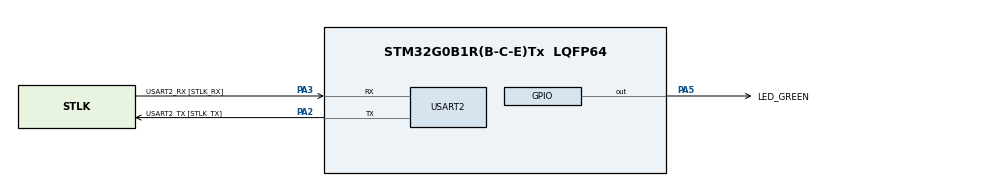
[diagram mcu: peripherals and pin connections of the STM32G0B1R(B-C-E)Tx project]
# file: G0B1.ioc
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FREERTOS.Tasks01=defaultTask,0,256,StartDefaultTask,Default,NULL,Dynamic,NULL,NULL;myTask02_Diagno,-3,256,StartTask02,Default,NULL,Dynamic,NULL,NULL
Mcu.Family=STM32G0
Mcu.Name=STM32G0B1R(B-C-E)Tx
Mcu.Package=LQFP64
NVIC.TIM17_FDCAN_IT1_IRQn=true\:3\:0\:false\:false\:true\:false\:true\:true\:true
NVIC.TimeBase=TIM17_FDCAN_IT1_IRQn
NVIC.TimeBaseIP=TIM17
NVIC.USART2_LPUART2_IRQn=true\:3\:0\:false\:false\:true\:true\:true\:true\:true
PA13.GPIO_Label=TMS
PA13.Mode=Serial_Wire
PA13.Signal=SYS_SWDIO
PA14-BOOT0.GPIO_Label=TCK
PA14-BOOT0.Mode=Serial_Wire
PA14-BOOT0.Signal=SYS_SWCLK
PA2.GPIO_Label=USART2_TX [STLK_TX]
PA2.Mode=Asynchronous
PA2.Signal=USART2_TX
PA3.GPIO_Label=USART2_RX [STLK_RX]
PA3.Mode=Asynchronous
PA3.Signal=USART2_RX
PA5.GPIO_Label=LED_GREEN
PA5.GPIO_Speed=GPIO_SPEED_FREQ_HIGH
PA5.Signal=GPIO_Output
PC13.Mode=SYS_WakeUp1
PC13.Signal=SYS_WKUP2
PC14-OSC32_IN\ (PC14).Mode=LSE-External-Oscillator
PC14-OSC32_IN\ (PC14).Signal=RCC_OSC32_IN
PC15-OSC32_OUT\ (PC15).Mode=LSE-External-Oscillator
PC15-OSC32_OUT\ (PC15).Signal=RCC_OSC32_OUT
PF0-OSC_IN\ (PF0).GPIO_Label=MCO
PF0-OSC_IN\ (PF0).Mode=HSE-External-Clock-Source
PF0-OSC_IN\ (PF0).Signal=RCC_OSC_IN
ProjectManager.HeapSize=0x200
ProjectManager.StackSize=0x400
ProjectManager.TargetToolchain=Makefile
RCC.AHBFreq_Value=16000000
RCC.CortexFreq_Value=16000000
RCC.EXTERNAL_CLOCK_VALUE=12288000
RCC.HCLKFreq_Value=16000000
RCC.HSE_VALUE=8000000
RCC.HSI48_VALUE=48000000
RCC.HSI_VALUE=16000000
RCC.SYSCLKFreq_VALUE=16000000
RCC.USBFreq_Value=48000000
RCC.VCOOutputFreq_Value=128000000
USART2.VirtualMode-Asynchronous=VM_ASYNC
VP_FREERTOS_VS_CMSIS_V1.Mode=CMSIS_V1
VP_SYS_VS_tim17.Mode=TIM17
board=NUCLEO-G0B1RE

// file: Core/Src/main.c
/* USER CODE BEGIN Header */
/**
 ******************************************************************************
 * @file           : main.c
 * @brief          : Main program body
 ******************************************************************************
 * @attention
 *
 * Copyright (c) 2023 STMicroelectronics.
 * All rights reserved.
 *
 * This software is licensed under terms that can be found in the LICENSE file
 * in the root directory of this software component.
 * If no LICENSE file comes with this software, it is provided AS-IS.
 *
 ******************************************************************************
 */
/* USER CODE END Header */
#include "main.h"
#include "cmsis_os.h"

/* USER CODE BEGIN Includes */
#define NANOPRINTF_USE_FIELD_WIDTH_FORMAT_SPECIFIERS 1
#define NANOPRINTF_USE_PRECISION_FORMAT_SPECIFIERS 1
#define NANOPRINTF_USE_FLOAT_FORMAT_SPECIFIERS 1
#define NANOPRINTF_USE_LARGE_FORMAT_SPECIFIERS 1
#define NANOPRINTF_USE_SMALL_FORMAT_SPECIFIERS 1
#define NANOPRINTF_USE_BINARY_FORMAT_SPECIFIERS 0
#define NANOPRINTF_USE_WRITEBACK_FORMAT_SPECIFIERS 0
#define NANOPRINTF_USE_ALT_FORM_FLAG 1
#define NANOPRINTF_IMPLEMENTATION
#include "nanoprintf.h"
#include "trice.h"
#include "trice_sidecar_main_c_B93C5977DE12EC66.h" // trice-bind: keep as last include before this file's Trice calls
/* USER CODE END Includes */

osThreadId defaultTaskHandle;
osThreadId myTask02_DiagnoHandle;
/* USER CODE BEGIN PV */
int LoopCount = 0;
static int TriceLocalLogLineStart = 1; // Keeps record prefixes aligned with logical output lines.
/* USER CODE END PV */

void SystemClock_Config(void);
static void MX_GPIO_Init(void);
static void MX_USART2_UART_Init(void);
void StartDefaultTask(void const* argument);
void StartTask02(void const* argument);

/* USER CODE BEGIN PFP */
static int TriceLocalStampPrefix(char*, size_t, uint16_t, uint8_t, uint32_t);
/* USER CODE END PFP */

/* USER CODE BEGIN 0 */
__weak int _close(void) { return -1; }
__weak int _lseek(void) { return -1; }
__weak int _read(void) { return -1; }
__weak int _write(void) { return -1; }

// TriceLocalUartWrite is intentionally blocking: only the low-priority logging
// task calls it, while producer tasks and interrupts merely enqueue Trices.
static void TriceLocalUartWrite(const char* text, size_t length) {
	for (size_t index = 0; index < length; ++index) {
		while (!LL_USART_IsActiveFlag_TXE_TXFNF(USART2)) {
		}
		LL_USART_TransmitData8(USART2, (uint8_t)text[index]);
	}
	if (length != 0u) {
		TriceLocalLogLineStart = text[length - 1u] == '\n' || text[length - 1u] == '\r';
	}
}

/* USER CODE END 0 */

int main(void) {
	/* USER CODE BEGIN 1 */
#if !TRICE_OFF
	TriceInit();
#endif
	/* USER CODE END 1 */

	/* MCU Configuration--------------------------------------------------------*/

	/* Reset of all peripherals, Initializes the Flash interface and the Systick. */
	HAL_Init();

	/* Configure the system clock */
	SystemClock_Config();

	/* Initialize all configured peripherals */
	MX_GPIO_Init();
	MX_USART2_UART_Init();
	/* USER CODE BEGIN 2 */
	// nanoprintf has the snprintf semantics required by both local-log hooks.
	// Trice-specific conversions use the selected internal formatter paths.
	UserTriceLogPrintfFn = npf_snprintf;
	UserTriceLogPrefixFn = TriceLocalStampPrefix;
	const uint16_t localLogSamples[] = {1u, 0x2au, 0x1234u};
	trice("msg:G0B1 local logging ready\n");
	triceS("text:runtime=[%s]\n", "hello from G0B1");
	triceS("text:width and precision=[%-12.5s]\n", "abcdefgh");
	trice32("float:single=%+.3f scientific=%.2e\n", aFloat(3.125f), aFloat(-0.03125f));
	trice64("float:double=%.9f compact=%.6g\n", aDouble(3.141592653589793), aDouble(123456.0));
	trice8("special:binary=%#b bool=%t octal=%O pointer=%p quoted=%q\n", 5u, 1u, 9u, 0xabu, 'A');
	triceS("text:quoted=%q\n", "line 1\n\"line 2\"");
	TRICE16_B("buffer:%04x \n", localLogSamples, sizeof(localLogSamples) / sizeof(localLogSamples[0]));

	/* USER CODE END 2 */

	/* Create the thread(s) */
	/* definition and creation of defaultTask */
	osThreadDef(defaultTask, StartDefaultTask, osPriorityNormal, 0, 256);
	defaultTaskHandle = osThreadCreate(osThread(defaultTask), NULL);

	/* definition and creation of myTask02_Diagno */
	osThreadDef(myTask02_Diagno, StartTask02, osPriorityIdle, 0, 256);
	myTask02_DiagnoHandle = osThreadCreate(osThread(myTask02_Diagno), NULL);

	/* Start scheduler */
	osKernelStart();
	/* We should never get here as control is now taken by the scheduler */
	/* Infinite loop */
	while (1) {

	}
}

void SystemClock_Config(void) {
	/* HSI configuration and activation */
	LL_RCC_HSI_Enable();
	while (LL_RCC_HSI_IsReady() != 1) {
	}

	/* Set AHB prescaler*/
	LL_RCC_SetAHBPrescaler(LL_RCC_SYSCLK_DIV_1);

	/* Sysclk activation on the HSI */
	LL_RCC_SetSysClkSource(LL_RCC_SYS_CLKSOURCE_HSI);
	while (LL_RCC_GetSysClkSource() != LL_RCC_SYS_CLKSOURCE_STATUS_HSI) {
	}

	/* Set APB1 prescaler*/
	LL_RCC_SetAPB1Prescaler(LL_RCC_APB1_DIV_1);
	/* Update CMSIS variable (which can be updated also through SystemCoreClockUpdate function) */
	LL_SetSystemCoreClock(16000000);

	/* Update the time base */
	if (HAL_InitTick(TICK_INT_PRIORITY) != HAL_OK) {
		Error_Handler();
	}
}

static void MX_USART2_UART_Init(void) {

	LL_USART_InitTypeDef USART_InitStruct = {0};

	LL_GPIO_InitTypeDef GPIO_InitStruct = {0};

	LL_RCC_SetUSARTClockSource(LL_RCC_USART2_CLKSOURCE_PCLK1);

	/* Peripheral clock enable */
	LL_APB1_GRP1_EnableClock(LL_APB1_GRP1_PERIPH_USART2);

	LL_IOP_GRP1_EnableClock(LL_IOP_GRP1_PERIPH_GPIOA);
	/**USART2 GPIO Configuration
	PA2   ------> USART2_TX
	PA3   ------> USART2_RX
	*/
	GPIO_InitStruct.Pin = USART2_TX_Pin;
	GPIO_InitStruct.Mode = LL_GPIO_MODE_ALTERNATE;
	GPIO_InitStruct.Speed = LL_GPIO_SPEED_FREQ_LOW;
	GPIO_InitStruct.OutputType = LL_GPIO_OUTPUT_PUSHPULL;
	GPIO_InitStruct.Pull = LL_GPIO_PULL_NO;
	GPIO_InitStruct.Alternate = LL_GPIO_AF_1;
	LL_GPIO_Init(USART2_TX_GPIO_Port, &GPIO_InitStruct);

	GPIO_InitStruct.Pin = USART2_RX_Pin;
	GPIO_InitStruct.Mode = LL_GPIO_MODE_ALTERNATE;
	GPIO_InitStruct.Speed = LL_GPIO_SPEED_FREQ_LOW;
	GPIO_InitStruct.OutputType = LL_GPIO_OUTPUT_PUSHPULL;
	GPIO_InitStruct.Pull = LL_GPIO_PULL_NO;
	GPIO_InitStruct.Alternate = LL_GPIO_AF_1;
	LL_GPIO_Init(USART2_RX_GPIO_Port, &GPIO_InitStruct);

	/* USART2 interrupt Init */
	NVIC_SetPriority(USART2_LPUART2_IRQn, 3);
	NVIC_EnableIRQ(USART2_LPUART2_IRQn);

	USART_InitStruct.PrescalerValue = LL_USART_PRESCALER_DIV1;
	USART_InitStruct.BaudRate = 115200;
	USART_InitStruct.DataWidth = LL_USART_DATAWIDTH_8B;
	USART_InitStruct.StopBits = LL_USART_STOPBITS_1;
	USART_InitStruct.Parity = LL_USART_PARITY_NONE;
	USART_InitStruct.TransferDirection = LL_USART_DIRECTION_TX_RX;
	USART_InitStruct.HardwareFlowControl = LL_USART_HWCONTROL_NONE;
	USART_InitStruct.OverSampling = LL_USART_OVERSAMPLING_16;
	LL_USART_Init(USART2, &USART_InitStruct);
	LL_USART_SetTXFIFOThreshold(USART2, LL_USART_FIFOTHRESHOLD_1_8);
	LL_USART_SetRXFIFOThreshold(USART2, LL_USART_FIFOTHRESHOLD_1_8);
	LL_USART_DisableFIFO(USART2);
	LL_USART_ConfigAsyncMode(USART2);

	LL_USART_Enable(USART2);

	/* Polling USART2 initialisation */
	while ((!(LL_USART_IsActiveFlag_TEACK(USART2))) || (!(LL_USART_IsActiveFlag_REACK(USART2)))) {
	}
}

static void MX_GPIO_Init(void) {
	LL_GPIO_InitTypeDef GPIO_InitStruct = {0};

	/* GPIO Ports Clock Enable */
	LL_IOP_GRP1_EnableClock(LL_IOP_GRP1_PERIPH_GPIOC);
	LL_IOP_GRP1_EnableClock(LL_IOP_GRP1_PERIPH_GPIOF);
	LL_IOP_GRP1_EnableClock(LL_IOP_GRP1_PERIPH_GPIOA);

	/**/
	LL_GPIO_ResetOutputPin(LED_GREEN_GPIO_Port, LED_GREEN_Pin);

	/**/
	GPIO_InitStruct.Pin = LED_GREEN_Pin;
	GPIO_InitStruct.Mode = LL_GPIO_MODE_OUTPUT;
	GPIO_InitStruct.Speed = LL_GPIO_SPEED_FREQ_HIGH;
	GPIO_InitStruct.OutputType = LL_GPIO_OUTPUT_PUSHPULL;
	GPIO_InitStruct.Pull = LL_GPIO_PULL_NO;
	LL_GPIO_Init(LED_GREEN_GPIO_Port, &GPIO_InitStruct);

}

/* USER CODE BEGIN 4 */
// TriceLocalStampPrefix mirrors the G0B1_inst host presentation at logical line
// starts. Unstamped records retain twelve-column alignment.
static int TriceLocalStampPrefix(char* buffer, size_t size, uint16_t id, uint8_t stampBits, uint32_t stamp) {
	(void)id;
	if (TriceLocalLogLineStart == 0) {
		if (size != 0u) {
			buffer[0] = '\0';
		}
		return 0;
	}
	switch (stampBits) {
	case 0u:
		return npf_snprintf(buffer, size, TRICE_LOCAL_LOG_STAMP0_FORMAT " ");
	case 16u: {
		return npf_snprintf(buffer, size,
		                    TRICE_LOCAL_LOG_STAMP_COLOR TRICE_LOCAL_LOG_STAMP16_FORMAT TRICE_LOCAL_LOG_STAMP_RESET " ",
		                    (unsigned int)(uint16_t)stamp);
	}
	case 32u: {
		uint32_t milliseconds = stamp % 1000u;
		uint32_t totalSeconds = stamp / 1000u;
		uint32_t seconds = totalSeconds % 60u;
		uint32_t totalMinutes = totalSeconds / 60u;
		uint32_t minutes = totalMinutes % 60u;
		uint32_t hours = totalMinutes / 60u;
		return npf_snprintf(buffer, size,
		                    TRICE_LOCAL_LOG_STAMP_COLOR TRICE_LOCAL_LOG_STAMP32_FORMAT TRICE_LOCAL_LOG_STAMP_RESET " ",
		                    (unsigned long)hours, (unsigned long)minutes, (unsigned long)seconds, (unsigned long)milliseconds);
	}
	default:
		if (size != 0u) {
			buffer[0] = '\0';
		}
		return -1;
	}
}
/* USER CODE END 4 */

void StartDefaultTask(void const* argument) {
	/* USER CODE BEGIN 5 */
	TRICE_UNUSED(argument)
	TRice("msg:StartDefaultTask\n");
	/* Infinite loop */
	for (;;) {
#if !TRICE_OFF
		// TriceCheck uses physical source line numbers as switch selectors. This
		// mirrors G0B1_inst while extending its former 2500 limit past the current
		// end of the shared test corpus.
		static int index = 0;
		if (index++ > 3200) {
			index = 0;
		}
		TriceCheck(index);
#endif
		osDelay(50);
	}
	/* USER CODE END 5 */
}

void StartTask02(void const* argument) {
	/* USER CODE BEGIN StartTask02 */
	TRICE_UNUSED(argument)
	TRice("msg:StartTask02:TriceLog to USART2\n");
	/* Infinite loop */
	for (;;) {
#if !TRICE_OFF
		// Static storage preserves the CubeMX-generated task stack size while
		// accommodating the longest enabled triceCheck format strings.
		static char text[512];
		int length;
		while ((length = TriceLog(text, sizeof(text))) > 0) {
			TriceLocalUartWrite(text, (size_t)length);
		}
		// A negative result consumed the offending complete record. The task
		// deliberately continues so later records can still be reported.
		TRICE_UNUSED(length)
#endif // #if !TRICE_OFF
		osDelay(10);
	}
	/* USER CODE END StartTask02 */
}

void HAL_TIM_PeriodElapsedCallback(TIM_HandleTypeDef* htim) {
	if (htim->Instance == TIM17) {
		HAL_IncTick();
	}
}

void Error_Handler(void) {
	__disable_irq();
	while (1) {
	}
}
